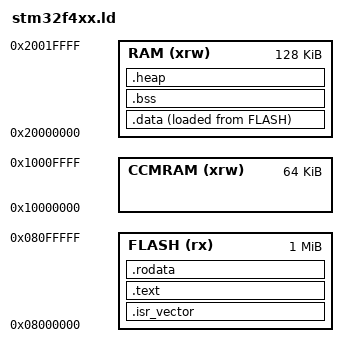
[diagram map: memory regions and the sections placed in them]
/*
 * FreeRTOS V202112.00
 * Copyright (C) 2020 Amazon.com, Inc. or its affiliates.  All Rights Reserved.
 *
 * Permission is hereby granted, free of charge, to any person obtaining a copy of
 * this software and associated documentation files (the "Software"), to deal in
 * the Software without restriction, including without limitation the rights to
 * use, copy, modify, merge, publish, distribute, sublicense, and/or sell copies of
 * the Software, and to permit persons to whom the Software is furnished to do so,
 * subject to the following conditions:
 *
 * The above copyright notice and this permission notice shall be included in all
 * copies or substantial portions of the Software.
 *
 * THE SOFTWARE IS PROVIDED "AS IS", WITHOUT WARRANTY OF ANY KIND, EXPRESS OR
 * IMPLIED, INCLUDING BUT NOT LIMITED TO THE WARRANTIES OF MERCHANTABILITY, FITNESS
 * FOR A PARTICULAR PURPOSE AND NONINFRINGEMENT. IN NO EVENT SHALL THE AUTHORS OR
 * COPYRIGHT HOLDERS BE LIABLE FOR ANY CLAIM, DAMAGES OR OTHER LIABILITY, WHETHER
 * IN AN ACTION OF CONTRACT, TORT OR OTHERWISE, ARISING FROM, OUT OF OR IN
 * CONNECTION WITH THE SOFTWARE OR THE USE OR OTHER DEALINGS IN THE SOFTWARE.
 *
 * http://www.FreeRTOS.org
 * http://aws.amazon.com/freertos
 *
 * 1 tab == 4 spaces!
 */

/* Entry Point */
ENTRY(Reset_Handler)

/* Memory areas */
MEMORY
{
    FLASH (rx)      : ORIGIN = 0x08000000, LENGTH = 1024K
    RAM (xrw)      : ORIGIN = 0x20000000, LENGTH = 128K
    CCMRAM (xrw)      : ORIGIN = 0x10000000, LENGTH = 64K
}

/* Highest address of the user mode stack */
_estack = 0x20020000;    /* end of RAM: ORIGIN(RAM) + LENGTH(RAM) */

/* Generate a link error if heap and stack don't fit into RAM */
_Min_Heap_Size = 0x2000;      /* required amount of heap  */
_Min_Stack_Size = 0x2000; /* required amount of stack */


SECTIONS
{
    .isr_vector :
    {
        . = ALIGN(4);
        KEEP(*(.isr_vector))
        . = ALIGN(4);
    } > FLASH

    .text :
    {
        . = ALIGN(4);
        *(.text)
        *(.text*)
        . = ALIGN(4);
        _etext = .;
    } > FLASH

    .rodata :
    {
        . = ALIGN(4);
        *(.rodata*)
        *(.constdata*)
        . = ALIGN(4);
    } > FLASH

    _sidata = LOADADDR(.data);
    
    .data :
    {
        . = ALIGN(4);
        _data = .;
        _sdata = .;
        *(.data)
        *(.data*)
        . = ALIGN(4);
        _edata = .;
    } >RAM AT> FLASH

    .bss :
    {
        . = ALIGN(4);
        _bss = .;
        _sbss = .;
        *(.bss)
        *(.bss*)
        _ebss = .;
    } >RAM
    
    .heap :
    {
        . = ALIGN(8);
        PROVIDE ( end = . );
        PROVIDE ( _end = . );
        _heap_bottom = .;
        . = . + _Min_Heap_Size;
        _heap_top = .;
        . = . + _Min_Stack_Size;
        . = ALIGN(8);
   } >RAM
   
   /* Set stack top to end of RAM, and stack limit move down by
    * size of stack_dummy section */
   __StackTop = ORIGIN(RAM) + LENGTH(RAM);
   __StackLimit = __StackTop - _Min_Stack_Size;
   PROVIDE(__stack = __StackTop);
     
  /* Check if data + heap + stack exceeds RAM limit */
  ASSERT(__StackLimit >= _heap_top, "region RAM overflowed with stack")
  
}
